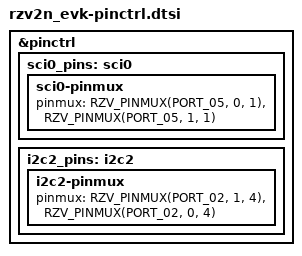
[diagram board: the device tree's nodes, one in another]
/*
 * Copyright (c) 2025 Renesas Electronics Corporation
 * SPDX-License-Identifier: Apache-2.0
 */

#include <zephyr/dt-bindings/gpio/gpio.h>
#include <zephyr/dt-bindings/pinctrl/renesas/pinctrl-rzv2n.h>

&pinctrl {
	/omit-if-no-ref/ sci0_pins: sci0 {
		sci0-pinmux {
			pinmux = <RZV_PINMUX(PORT_05, 0, 1)>, /* TXD */
				 <RZV_PINMUX(PORT_05, 1, 1)>; /* RXD */
		};
	};

	/omit-if-no-ref/ i2c2_pins: i2c2 {
		i2c2-pinmux {
			pinmux = <RZV_PINMUX(PORT_02, 1, 4)>, /* SCL */
				 <RZV_PINMUX(PORT_02, 0, 4)>; /* SDA */
		};
	};
};
